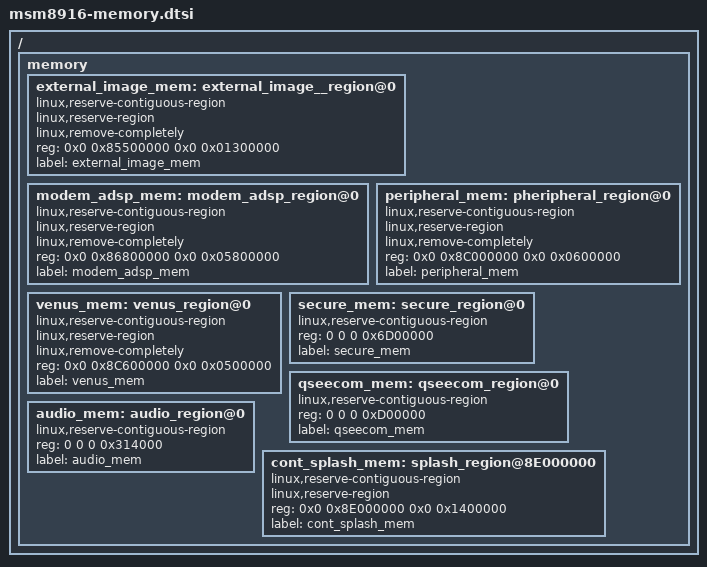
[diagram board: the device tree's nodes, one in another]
/* Copyright (c) 2014, The Linux Foundation. All rights reserved.
 *
 * This program is free software; you can redistribute it and/or modify
 * it under the terms of the GNU General Public License version 2 and
 * only version 2 as published by the Free Software Foundation.
 *
 * This program is distributed in the hope that it will be useful,
 * but WITHOUT ANY WARRANTY; without even the implied warranty of
 * MERCHANTABILITY or FITNESS FOR A PARTICULAR PURPOSE.  See the
 * GNU General Public License for more details.
 */

#include "msm8916-ion.dtsi"

/ {
	memory {
		#address-cells = <2>;
		#size-cells = <2>;

/* Additionally Reserved 6MB for TIMA and Increased the TZ app size
 * by 2MB [total 8 MB ]
 */
		external_image_mem: external_image__region@0 {
			linux,reserve-contiguous-region;
			linux,reserve-region;
			linux,remove-completely;
			reg = <0x0 0x85500000 0x0 0x01300000>;
			label = "external_image_mem";
		};

		modem_adsp_mem: modem_adsp_region@0 {
			linux,reserve-contiguous-region;
			linux,reserve-region;
			linux,remove-completely;
			reg = <0x0 0x86800000 0x0 0x05800000>;
			label = "modem_adsp_mem";
		};

		peripheral_mem: pheripheral_region@0 {
			linux,reserve-contiguous-region;
			linux,reserve-region;
			linux,remove-completely;
			reg = <0x0 0x8C000000 0x0 0x0600000>;
			label = "peripheral_mem";
		};

		venus_mem: venus_region@0 {
			linux,reserve-contiguous-region;
			linux,reserve-region;
			linux,remove-completely;
			reg = <0x0 0x8C600000 0x0 0x0500000>;
			label = "venus_mem";
		};

		secure_mem: secure_region@0 {
			linux,reserve-contiguous-region;
			reg = <0 0 0 0x6D00000>;
			label = "secure_mem";
		};

		qseecom_mem: qseecom_region@0 {
			linux,reserve-contiguous-region;
			reg = <0 0 0 0xD00000>;
			label = "qseecom_mem";
		};

		audio_mem: audio_region@0 {
			linux,reserve-contiguous-region;
			reg = <0 0 0 0x314000>;
			label = "audio_mem";
		};

		cont_splash_mem: splash_region@8E000000 {
			linux,reserve-contiguous-region;
			linux,reserve-region;
			reg = <0x0 0x8E000000 0x0 0x1400000>;
			label = "cont_splash_mem";
		};
	};
};
